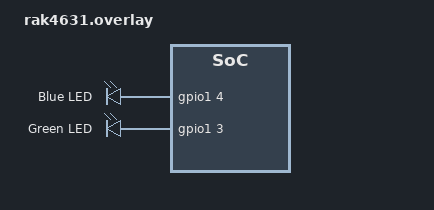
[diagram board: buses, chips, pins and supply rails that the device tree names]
/ {
	chosen {
		zephyr,code-partition = &boot_partition;
	};

	aliases {
		blue-led = &blue_led;
		green-led = &green_led;
	};

	leds {
		compatible = "gpio-leds";
		blue_led: led_2 {
			gpios = <&gpio1 4 GPIO_ACTIVE_HIGH>;
			label = "Blue LED";
		};
		green_led: led_1 {
			gpios = <&gpio1 3 GPIO_ACTIVE_HIGH>;
			label = "Green LED";
		};
	};
};

&reg1 {
	regulator-initial-mode = <NRF5X_REG_MODE_DCDC>;
};
